# PN73xxAU register map
File version: 2
CPU: CM0 r0p0, little endian, no MPU, no FPU, 2 interrupt priority bits
Registers are 32-bit, read-write, reset 0x0 unless marked. A register's access mark holds for its fields unless they carry their own. Offsets are from the block's base; [hi:lo] are bit positions; <NAME> marks a mode.

## PMU — Power Management Unit
Base 0x40008000
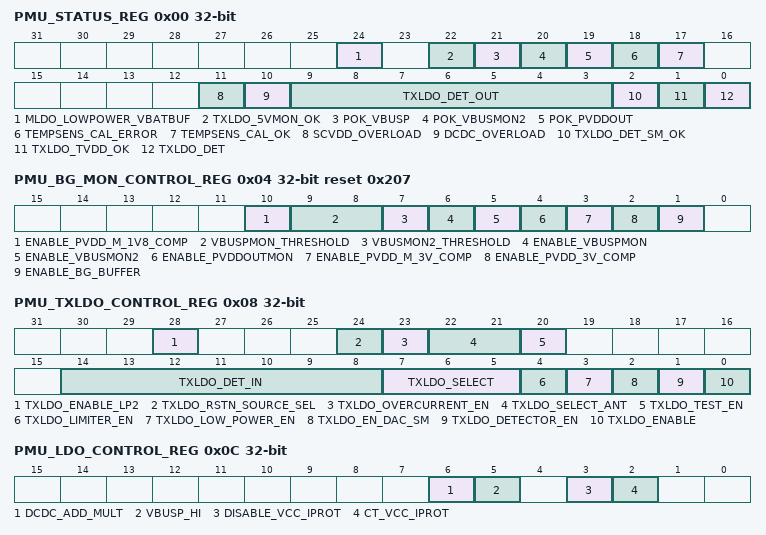
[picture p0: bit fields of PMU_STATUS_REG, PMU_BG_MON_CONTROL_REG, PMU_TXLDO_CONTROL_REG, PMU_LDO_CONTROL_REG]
0x00 PMU_STATUS_REG ro — Indicating status of sequence or operation completion on different blocks: tempsensor/dcdc/ldo
  [24] MLDO_LOWPOWER_VBATBUF — high to indicate that the vbat ldo is in lowpower
  [22] TXLDO_5VMON_OK — TXLDO 5V monitor output high/low.
  [21] POK_VBUSP — output of vbusp monitor
  [20] POK_VBUSMON2 — output of vbus monitor2
  [19] POK_PVDDOUT — output of pvdd_out monitor
  [18] TEMPSENS_CAL_ERROR — Indicates a calibration error. Goes high if:- fine is at maximum value and tempsens_error_irq is not high
  [17] TEMPSENS_CAL_OK — Temperature sensor calibration ok. Means calibration is done for current sensor. Note that this signal will rise for each trimmed sensor. Set and cleared by hardware.
  [11] SCVDD_OVERLOAD — high when Ron is incremented
  [10] DCDC_OVERLOAD — high when Ron is decremented
  [9:3] TXLDO_DET_OUT — [6:0] - Output of State Machine detection
  [2] TXLDO_DET_SM_OK — Signal that indicates to Digital & SW that State Machine work is done
  [1] TXLDO_TVDD_OK — Signal that indicates State Machine work is done
  [0] TXLDO_DET — Indicates the detection threshold
0x04 PMU_BG_MON_CONTROL_REG reset 0x207 — Enabling comparators and bang gaps
  [10] ENABLE_PVDD_M_1V8_COMP — Enable for PVDD_M 1.8V comparator
  [9:8] VBUSPMON_THRESHOLD — 00 for 2.7V, 01 for 3V and 10 for 3.9V
  [7] VBUSMON2_THRESHOLD — 0 for 2.5V and 1 for 4V
  [6] ENABLE_VBUSPMON — enable for vbusp monitor
  [5] ENABLE_VBUSMON2 — enable for vbus monitor2
  [4] ENABLE_PVDDOUTMON — enable for pvddout monitor
  [3] ENABLE_PVDD_M_3V_COMP — high to enable 3v comparator for PVDD_M
  [2] ENABLE_PVDD_3V_COMP — high to enable 3v comparator for PVDD
  [1] ENABLE_BG_BUFFER — high to enable reference for memories
0x08 PMU_TXLDO_CONTROL_REG — Register bits for TXLDO sequence for reader and card detection
  [28] TXLDO_ENABLE_LP2 — Enable the 2nd regulator
  [24] TXLDO_RSTN_SOURCE_SEL — Source selection bit of TXLDO_digi resetn. 0: resetn source = rst_pcr_system_n 1: resetn source = (~rst_pcr_system_n or txldo_enable)
  [23] TXLDO_OVERCURRENT_EN — high to enable overcurrent detection
  [22:21] TXLDO_SELECT_ANT — selection of antenna size 0: large 1: small
  [20] TXLDO_TEST_EN — Signal used only when testing TXLDO
  [14:8] TXLDO_DET_IN — Selection of Current Detection value
  [7:5] TXLDO_SELECT — Selection of Tvdd supply 0: tvdd = 3.1V 1: tvdd = 2.7V
  [4] TXLDO_LIMITER_EN — Activates the current limiter
  [3] TXLDO_LOW_POWER_EN — Activates the low-power mode
  [2] TXLDO_EN_DAC_SM — Selects current measurement using state machine
  [1] TXLDO_DETECTOR_EN — Activates the Current Detection
  [0] TXLDO_ENABLE — Enable the whole block TXLDO if seq not used
0x0C PMU_LDO_CONTROL_REG — LDO configurations : Enabling and current limit information
  [6] DCDC_ADD_MULT — Used to increment the multipliers of RON1 by 1. Useful after validation of current capability.
  [5] VBUSP_HI — CT channel detects the presence and starts the CT sequence. HIGH: VBUSP > 3.9V. LOW: VBUSP < =3.9V.
  [3] DISABLE_VCC_IPROT — Required to disable vcc current protection
  [2] CT_VCC_IPROT ro — To be filled from datasheet
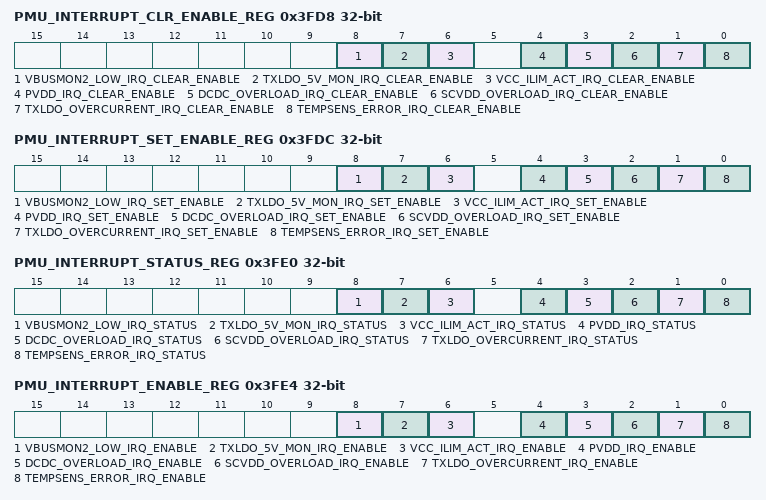
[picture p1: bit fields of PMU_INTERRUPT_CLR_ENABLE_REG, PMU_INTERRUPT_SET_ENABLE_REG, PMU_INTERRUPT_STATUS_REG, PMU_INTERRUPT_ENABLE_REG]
0x3FD8 PMU_INTERRUPT_CLR_ENABLE_REG wo — Interrupt(current limit or temperature) clear enable
  [8] VBUSMON2_LOW_IRQ_CLEAR_ENABLE — Vbus monitor 2 going low interrupt clear enable
  [7] TXLDO_5V_MON_IRQ_CLEAR_ENABLE — Txldo 5v monitor irq clear enable
  [6] VCC_ILIM_ACT_IRQ_CLEAR_ENABLE — vcc current limiter active irq clear enable. Automatically cleared after 2 cycles if set by software
  [4] PVDD_IRQ_CLEAR_ENABLE — pvdd irq clear enable.Automatically cleared after 2 cycles if set by software
  [3] DCDC_OVERLOAD_IRQ_CLEAR_ENABLE — dcdc overload clear enable.Automatically cleared after 2 cycles if set by software
  [2] SCVDD_OVERLOAD_IRQ_CLEAR_ENABLE — scvdd overload clear enable.Automatically cleared after 2 cycles if set by software
  [1] TXLDO_OVERCURRENT_IRQ_CLEAR_ENABLE — txldo overcurrent irq clear enable.Automatically cleared after 2 cycles if set by software
  [0] TEMPSENS_ERROR_IRQ_CLEAR_ENABLE — temperature sensor calibration irq clear enable.Automatically cleared after 2 cycles if set by software
0x3FDC PMU_INTERRUPT_SET_ENABLE_REG wo — Interrupt(current limit or temperature) set enable
  [8] VBUSMON2_LOW_IRQ_SET_ENABLE — Vbus monitor 2 going low interrupt set enable
  [7] TXLDO_5V_MON_IRQ_SET_ENABLE
  [6] VCC_ILIM_ACT_IRQ_SET_ENABLE — vcc current limiter active irq set enable. Automatically cleared after 2 cycles if set by software
  [4] PVDD_IRQ_SET_ENABLE — pvdd irq set enable. Automatically cleared after 2 cycles if set by software
  [3] DCDC_OVERLOAD_IRQ_SET_ENABLE — dcdc overload irq set enable.Automatically cleared after 2 cycles if set by software
  [2] SCVDD_OVERLOAD_IRQ_SET_ENABLE — scvdd overload irq set enable.Automatically cleared after 2 cycles if set by software
  [1] TXLDO_OVERCURRENT_IRQ_SET_ENABLE — txldo_overcurrent irq set enable.Automatically cleared after 2 cycles if set by software
  [0] TEMPSENS_ERROR_IRQ_SET_ENABLE — temperature sensor irq set enable.Automatically cleared after 2 cycles if set by software
0x3FE0 PMU_INTERRUPT_STATUS_REG ro — Interrupt(current limit or temperature) status
  [8] VBUSMON2_LOW_IRQ_STATUS — Vbus monitor 2 going low interrupt status
  [7] TXLDO_5V_MON_IRQ_STATUS — TXLDO_5V_MON_IRQ status register. .Automatically cleared after 2 cycles if set by software
  [6] VCC_ILIM_ACT_IRQ_STATUS — vcc current limiter active irq status. Automatically cleared after 2 cycles if by software
  [4] PVDD_IRQ_STATUS — pvdd irq status. Automatically cleared after 2 cycles if by software
  [3] DCDC_OVERLOAD_IRQ_STATUS — dcdc overload irq status.Automatically cleared after 2 cycles if by software
  [2] SCVDD_OVERLOAD_IRQ_STATUS — scvdd overload irq status.Automatically cleared after 2 cycles if by software
  [1] TXLDO_OVERCURRENT_IRQ_STATUS — txldo_overcurrent irq status.Automatically cleared after 2 cycles if by software
  [0] TEMPSENS_ERROR_IRQ_STATUS — temperature sensor irq status.Automatically cleared after 2 cycles if by software
0x3FE4 PMU_INTERRUPT_ENABLE_REG ro — Interrupt(current limit or temperature) enable
  [8] VBUSMON2_LOW_IRQ_ENABLE — Vbus monitor 2 going low interrupt enable
  [7] TXLDO_5V_MON_IRQ_ENABLE — TXLDO_5V_MON_IRQ enable status register. .Automatically cleared after 2 cycles if set by software
  [6] VCC_ILIM_ACT_IRQ_ENABLE — vcc current limiter active irq enable. Automatically cleared after 2 cycles if by software
  [4] PVDD_IRQ_ENABLE — pvdd irq enable. Automatically cleared after 2 cycles if by software
  [3] DCDC_OVERLOAD_IRQ_ENABLE — dcdc overload irq enable.Automatically cleared after 2 cycles if by software
  [2] SCVDD_OVERLOAD_IRQ_ENABLE — scvdd overload irq enable.Automatically cleared after 2 cycles if by software
  [1] TXLDO_OVERCURRENT_IRQ_ENABLE — txldo_overcurrent irq enable.Automatically cleared after 2 cycles if by software
  [0] TEMPSENS_ERROR_IRQ_ENABLE — temperature sensor irq enable.Automatically cleared after 2 cycles if by software
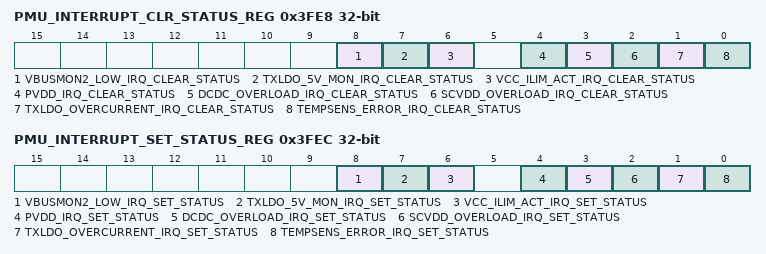
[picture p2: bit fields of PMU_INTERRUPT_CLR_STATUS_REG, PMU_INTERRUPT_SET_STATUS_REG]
0x3FE8 PMU_INTERRUPT_CLR_STATUS_REG wo — Interrupt(current limit or temperature) clear status
  [8] VBUSMON2_LOW_IRQ_CLEAR_STATUS — Vbus monitor 2 going low interrupt clear status
  [7] TXLDO_5V_MON_IRQ_CLEAR_STATUS — TXLDO_5V_MON_IRQ clear status register. .Automatically cleared after 2 cycles if set by software
  [6] VCC_ILIM_ACT_IRQ_CLEAR_STATUS — vcc current limiter active irq clear status.Automatically cleared after 2 cycles if clear by software
  [4] PVDD_IRQ_CLEAR_STATUS — pvdd irq clear status.Automatically cleared after 2 cycles if clear by software
  [3] DCDC_OVERLOAD_IRQ_CLEAR_STATUS — dcdc overload irq clear status.Automatically cleared after 2 cycles if clear by software
  [2] SCVDD_OVERLOAD_IRQ_CLEAR_STATUS — scvdd overload irq clear status.Automatically cleared after 2 cycles if clear by software
  [1] TXLDO_OVERCURRENT_IRQ_CLEAR_STATUS — txldo_overcurrent irq clear status.Automatically cleared after 2 cycles if set by software
  [0] TEMPSENS_ERROR_IRQ_CLEAR_STATUS — temp sensor irq clear status.Automatically cleared after 2 cycles if set by software
0x3FEC PMU_INTERRUPT_SET_STATUS_REG wo — Interrupt(current limit or temperature) set status
  [8] VBUSMON2_LOW_IRQ_SET_STATUS — Vbus monitor 2 going low interrupt set status
  [7] TXLDO_5V_MON_IRQ_SET_STATUS — TXLDO_5V_MON_IRQ set status register. .Automatically cleared after 2 cycles if set by software
  [6] VCC_ILIM_ACT_IRQ_SET_STATUS — vcc current limiter active irq set status.Automatically cleared after 2 cycles if set by software
  [4] PVDD_IRQ_SET_STATUS — pvdd irq set status.Automatically cleared after 2 cycles if set by software
  [3] DCDC_OVERLOAD_IRQ_SET_STATUS — dcdc overload irq set status.Automatically cleared after 2 cycles if set by software
  [2] SCVDD_OVERLOAD_IRQ_SET_STATUS — scvdd overload irq set status.Automatically cleared after 2 cycles if set by software
  [1] TXLDO_OVERCURRENT_IRQ_SET_STATUS — txldo_overcurrent irq set status.Automatically cleared after 2 cycles if set by software
  [0] TEMPSENS_ERROR_IRQ_SET_STATUS — temp sensor irq set status.Automatically cleared after 2 cycles if set by software
